AUTOSAR XML (schema 4-0-3)
package /ComponentTypes
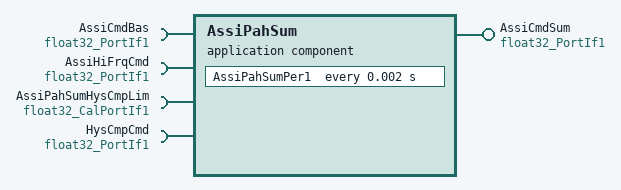
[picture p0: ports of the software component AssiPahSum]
  application sw component type AssiPahSum
    provide port AssiCmdSum: nonqueued-sender-com-spec{data-element=Val, init-value=0}, provided-interface=float32_PortIf1
    4 x require port:
      AssiCmdBas: nonqueued-receiver-com-spec{data-element=Val, filter=data-filter-type=ALWAYS, init-value=0}, required-interface=float32_PortIf1
      AssiHiFrqCmd: nonqueued-receiver-com-spec{data-element=Val, filter=data-filter-type=ALWAYS, init-value=0}, required-interface=float32_PortIf1
      AssiPahSumHysCmpLim: parameter-require-com-spec{init-value=0.2, parameter=Val}, required-interface=float32_CalPortIf1
      HysCmpCmd: nonqueued-receiver-com-spec{data-element=Val, filter=data-filter-type=ALWAYS, init-value=0}, required-interface=float32_PortIf1
    behavior AssiPahSum_InternalBehavior
      timing event TMT_AssiPahSumPer1: start-on-event=AssiPahSumPer1, period=0.002
      port-api-options:
        enable-take-address=false, indirect-api=false, port=AssiCmdBas
        enable-take-address=false, indirect-api=false, port=AssiCmdSum
      runnable AssiPahSumPer1
        data-receive-point-by-arguments:
          access REC_AssiCmdBas_Val_1: accessed-variable=AssiCmdBas.Val
          access REC_AssiHiFrqCmd_Val_1: accessed-variable=AssiHiFrqCmd.Val
          access REC_HysCmpCmd_Val_1: accessed-variable=HysCmpCmd.Val
        data-send-points:
          access SEND_AssiCmdSum_Val_1: accessed-variable=AssiCmdSum.Val
  swc implementation AssiPahSum_Implementation: behavior=AssiPahSum_InternalBehavior
    code-descriptors:
      code Default: artifact-descriptors=autosar-engineering-object={short-label=Default, category=SWSRC}
